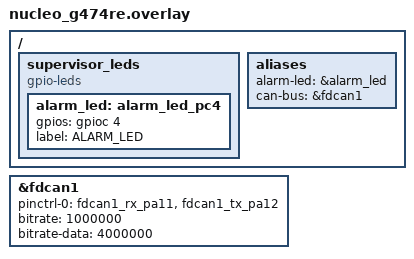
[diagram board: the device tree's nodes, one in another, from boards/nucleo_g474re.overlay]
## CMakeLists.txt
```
cmake_minimum_required(VERSION 3.20.0)

set(CMAKE_CXX_STANDARD 20)
set(CMAKE_CXX_STANDARD_REQUIRED ON)
set(CMAKE_CXX_EXTENSIONS OFF)

find_package(Zephyr REQUIRED HINTS $ENV{ZEPHYR_BASE})
project(supervisor_node LANGUAGES CXX)

target_sources(app PRIVATE
  ${CMAKE_CURRENT_SOURCE_DIR}/src/main.cpp
  ${CMAKE_CURRENT_SOURCE_DIR}/src/gpio_overlay.cpp
  ${CMAKE_CURRENT_SOURCE_DIR}/src/heartbeat_monitor.cpp
  ${CMAKE_CURRENT_SOURCE_DIR}/src/alarm_logic.cpp
  ${CMAKE_CURRENT_SOURCE_DIR}/src/supervisor_manager.cpp
  ${CMAKE_CURRENT_SOURCE_DIR}/../common/supervisor/src/can_bus_driver.cpp
  ${CMAKE_CURRENT_SOURCE_DIR}/../common/supervisor/src/message_codec.cpp
)

# Strict warnings apply only to our own application code, not to
# Zephyr's kernel/drivers/HAL/CMSIS sources (which are not -Werror clean
# on this toolchain and are not ours to fix).
target_compile_options(app PRIVATE
  -Wall
  -Wextra
  -Werror
  -Wvolatile
)

target_include_directories(app PRIVATE
  ${CMAKE_CURRENT_SOURCE_DIR}/include
  ${CMAKE_CURRENT_SOURCE_DIR}/../common/supervisor/include
)
```

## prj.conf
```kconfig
# ---- C++ support ------------------------------------------------------
CONFIG_CPP=y
CONFIG_STD_CPP20=y
CONFIG_NEWLIB_LIBC=y
CONFIG_GLIBCXX_LIBCPP=y

# ---- No heap allocation (Rule 1) --------------------------------------
CONFIG_HEAP_MEM_POOL_SIZE=0

# ---- Threading / stack watermarks (Rule 6) -----------------------------
CONFIG_THREAD_ANALYZER=y
CONFIG_THREAD_ANALYZER_AUTO=y
CONFIG_THREAD_NAME=y
CONFIG_MAIN_STACK_SIZE=2048

# ---- CAN-FD -------------------------------------------------------------
CONFIG_CAN=y
CONFIG_CAN_FD_MODE=y

# ---- GPIO (alarm LED) --------------------------------------------------
CONFIG_GPIO=y

# ---- Logging ----------------------------------------------------------
CONFIG_LOG=y
CONFIG_LOG_MODE_IMMEDIATE=y

# ---- Assertions ---------------------------------------------------------
CONFIG_ASSERT=y
```

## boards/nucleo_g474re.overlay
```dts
/*
 * Supervisor Node device tree overlay.
 * Binds: FDCAN1 (CAN bus), PC4 alarm LED.
 *
 * Application code SHALL NEVER reference these nodes directly; only
 * gpio_overlay.cpp is permitted to consume DT_ALIAS()/DT_NODELABEL()
 * macros generated from this file.
 */

&fdcan1 {
	status = "okay";
	pinctrl-0 = <&fdcan1_rx_pa11 &fdcan1_tx_pa12>;
	pinctrl-names = "default";
	bitrate = <1000000>;
	bitrate-data = <4000000>;
};

/ {
	supervisor_leds {
		compatible = "gpio-leds";
		alarm_led: alarm_led_pc4 {
			gpios = <&gpioc 4 GPIO_ACTIVE_HIGH>;
			label = "ALARM_LED";
		};
	};

	aliases {
		alarm-led = &alarm_led;
		can-bus = &fdcan1;
	};
};
```

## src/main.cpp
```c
/// @file main.cpp
/// @brief Supervisor Node entry point. Wires gpio_overlay -> CAN RX ->
///        supervisor_manager (Mediator) -> {alarm LED, RUN/STOP CAN TX}.
#include <zephyr/kernel.h>
#include <zephyr/logging/log.h>

#include "can_bus_driver.hpp"
#include "gpio_overlay.hpp"
#include "message_codec.hpp"
#include "supervisor_manager.hpp"

LOG_MODULE_REGISTER(supervisor_node_main, LOG_LEVEL_INF);

namespace {

using hce::supervisor_node::GpioOverlay;
using hce::supervisor_node::SupervisorManager;

constexpr uint32_t kMonitoringPeriodMs = 200U;
constexpr size_t kMonitorThreadStackSize = 2048U;
constexpr int kMonitorThreadPriority = 5;

GpioOverlay g_overlay;
hce::supervisor::CanBusDriver* g_can_bus = nullptr;
SupervisorManager* g_supervisor_manager = nullptr;

alignas(hce::supervisor::CanBusDriver) uint8_t g_can_bus_storage[sizeof(hce::supervisor::CanBusDriver)];
alignas(SupervisorManager) uint8_t g_supervisor_manager_storage[sizeof(SupervisorManager)];

/// @brief Copies an incoming CAN-FD frame's data bytes into a fixed-size
///        payload without any heap allocation.
hce::supervisor::MessageCodec::Payload ExtractPayload(const can_frame* frame) {
    hce::supervisor::MessageCodec::Payload payload{};
    for (uint8_t i = 0U; i < hce::supervisor::MessageCodec::kPayloadBytes && i < frame->dlc; ++i) {
        payload[i] = frame->data[i];
    }
    return payload;
}

extern "C" void OnPressureRx(const device* /*dev*/, can_frame* frame, void* /*user_data*/) {
    g_supervisor_manager->OnPressureReceived(ExtractPayload(frame));
}

extern "C" void OnFlowRx(const device* /*dev*/, can_frame* frame, void* /*user_data*/) {
    g_supervisor_manager->OnFlowReceived(ExtractPayload(frame));
}

extern "C" void OnSensorHeartbeatRx(const device* /*dev*/, can_frame* /*frame*/, void* /*user_data*/) {
    g_supervisor_manager->OnSensorHeartbeatReceived();
}

extern "C" void OnMotorHeartbeatRx(const device* /*dev*/, can_frame* /*frame*/, void* /*user_data*/) {
    g_supervisor_manager->OnMotorHeartbeatReceived();
}

void MonitorThreadEntry(void* /*p1*/, void* /*p2*/, void* /*p3*/) {
    while (true) {
        g_supervisor_manager->Tick();
        k_msleep(kMonitoringPeriodMs);
    }
}

K_THREAD_STACK_DEFINE(g_monitor_thread_stack, kMonitorThreadStackSize);
k_thread g_monitor_thread{};

}  // namespace

int main() {
    LOG_INF("Supervisor Node booting");

    if (!g_overlay.Init()) {
        LOG_ERR("gpio_overlay init failed - halting");
        return -1;
    }

    g_can_bus = new (g_can_bus_storage) hce::supervisor::CanBusDriver(g_overlay.CanDevice());
    g_supervisor_manager = new (g_supervisor_manager_storage) SupervisorManager(g_overlay, *g_can_bus);

    if (!g_can_bus->Init()) {
        LOG_ERR("CAN bus init failed - halting");
        return -1;
    }

    g_can_bus->AddRxFilter(hce::supervisor::CanId::kPressure, OnPressureRx, nullptr);
    g_can_bus->AddRxFilter(hce::supervisor::CanId::kFlow, OnFlowRx, nullptr);
    g_can_bus->AddRxFilter(hce::supervisor::CanId::kSensorHeartbeat, OnSensorHeartbeatRx, nullptr);
    g_can_bus->AddRxFilter(hce::supervisor::CanId::kMotorHeartbeat, OnMotorHeartbeatRx, nullptr);

    k_thread_create(&g_monitor_thread, g_monitor_thread_stack, kMonitorThreadStackSize,
                     MonitorThreadEntry, nullptr, nullptr, nullptr, kMonitorThreadPriority, 0,
                     K_NO_WAIT);
    k_thread_name_set(&g_monitor_thread, "supervisor_monitor");

    LOG_INF("Supervisor Node running");
    return 0;
}
```

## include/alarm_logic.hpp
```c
/// @file alarm_logic.hpp
/// @brief Combined pressure/flow/heartbeat fault evaluation.
///
/// Fault condition (per system safety spec):
///   (Pressure > kPressureThresholdPa AND Flow < kFlowThresholdLpm)
///   OR ThreeConsecutiveSensorHeartbeatsMissed
///   OR ThreeConsecutiveMotorHeartbeatsMissed
///
/// Note: pressure-high and flow-low are evaluated as a COMBINED condition
/// (both must be true together), not as two independent single-sensor
/// faults - this reflects a deliberate safety-logic update from
/// independent-fault evaluation to a combined-fault evaluation.
#pragma once

#include <cstdint>

namespace hce::supervisor_node {

/// @brief Inputs the alarm evaluation needs on any given tick.
struct AlarmInputs {
    float pressure_pa;
    bool pressure_valid;
    float flow_lpm;
    bool flow_valid;
    bool sensor_heartbeat_faulted;
    bool motor_heartbeat_faulted;
};

/// @brief Stateless fault-evaluation strategy (Strategy pattern: the
///        evaluation rule is isolated behind Evaluate() so it can be
///        swapped/tested independently of CAN transport or GPIO).
class AlarmLogic {
public:
    static constexpr float kPressureThresholdPa = 1025.0F;
    static constexpr float kFlowThresholdLpm = 60.0F;

    /// @brief Evaluate the combined fault condition.
    /// @return true if a fault (STOP condition) is present.
    bool Evaluate(const AlarmInputs& inputs) const;
};

}  // namespace hce::supervisor_node
```

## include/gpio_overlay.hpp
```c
/// @file gpio_overlay.hpp
/// @brief Sole layer permitted to reference Device Tree bindings for the
///        Supervisor Node.
#pragma once

#include <cstdint>

#include <zephyr/device.h>
#include <zephyr/drivers/gpio.h>

namespace hce::supervisor_node {

/// @brief Thin, mockable wrapper around all Supervisor Node DT-bound devices.
class GpioOverlay {
public:
    GpioOverlay() = default;

    bool Init();

    /// @brief CAN-FD controller device (FDCAN1).
    const device* CanDevice() const { return can_dev_; }

    /// @brief Drive the alarm LED (PC4).
    bool SetAlarmLed(bool on);

private:
    const device* can_dev_ = nullptr;
    gpio_dt_spec alarm_led_spec_{};
    bool initialized_ = false;
};

}  // namespace hce::supervisor_node
```

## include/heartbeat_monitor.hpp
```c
/// @file heartbeat_monitor.hpp
/// @brief Tracks liveness of the Sensor Node and Motor Node heartbeats.
///        A node is declared faulted after three consecutive missed
///        heartbeats (600 ms at the 200 ms heartbeat period).
#pragma once

#include <cstdint>

namespace hce::supervisor_node {

/// @brief Per-remote-node liveness tracker.
class NodeLivenessTracker {
public:
    static constexpr uint8_t kMaxConsecutiveMisses = 3U;

    /// @brief Call when a heartbeat frame is received from this node.
    void OnHeartbeatReceived();

    /// @brief Call once per supervisor monitoring tick (200 ms) to age
    ///        out the current window and evaluate for missed heartbeats.
    void OnMonitoringTick();

    /// @brief true if the node has missed kMaxConsecutiveMisses in a row.
    bool IsFaulted() const { return consecutive_misses_ >= kMaxConsecutiveMisses; }

private:
    uint8_t consecutive_misses_ = 0U;
    bool received_since_last_tick_ = false;
};

/// @brief Aggregates liveness for both remote nodes the Supervisor watches.
class HeartbeatMonitor {
public:
    void OnSensorHeartbeatReceived() { sensor_tracker_.OnHeartbeatReceived(); }
    void OnMotorHeartbeatReceived() { motor_tracker_.OnHeartbeatReceived(); }

    /// @brief Call once per 200 ms supervisor monitoring tick.
    void OnMonitoringTick();

    bool IsSensorNodeFaulted() const { return sensor_tracker_.IsFaulted(); }
    bool IsMotorNodeFaulted() const { return motor_tracker_.IsFaulted(); }

private:
    NodeLivenessTracker sensor_tracker_;
    NodeLivenessTracker motor_tracker_;
};

}  // namespace hce::supervisor_node
```

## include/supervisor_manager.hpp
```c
/// @file supervisor_manager.hpp
/// @brief Mediator between CAN RX (pressure/flow/heartbeats), alarm_logic,
///        heartbeat_monitor and CAN TX (RUN/STOP). Implements the Mediator
///        design pattern (Rule 4): CAN input handling, fault evaluation and
///        command dispatch never reference each other directly, only
///        through SupervisorManager.
#pragma once

#include <cstdint>

#include "alarm_logic.hpp"
#include "can_bus_driver.hpp"
#include "gpio_overlay.hpp"
#include "heartbeat_monitor.hpp"
#include "message_codec.hpp"

namespace hce::supervisor_node {

/// @brief Supervisor RUN/STOP output state.
enum class SupervisorState : uint8_t {
    kRun = 0U,
    kStop = 1U,
};

/// @brief Top-level Supervisor Node coordinator.
class SupervisorManager {
public:
    SupervisorManager(GpioOverlay& overlay, hce::supervisor::ICanBusDriver& can_bus);

    // ---- CAN RX handlers (called from ISR-safe deferred context) --------
    void OnPressureReceived(const hce::supervisor::MessageCodec::Payload& payload);
    void OnFlowReceived(const hce::supervisor::MessageCodec::Payload& payload);
    void OnSensorHeartbeatReceived();
    void OnMotorHeartbeatReceived();

    /// @brief Evaluate fault logic and drive alarm LED + RUN/STOP CAN
    ///        output. Intended to be called every 200 ms (Supervisor
    ///        Monitoring period) from a dedicated thread.
    void Tick();

    SupervisorState State() const { return state_; }

private:
    void TransmitStopCommand();
    void TransmitRunCommand();

    GpioOverlay& overlay_;
    hce::supervisor::ICanBusDriver& can_bus_;
    HeartbeatMonitor heartbeat_monitor_;
    AlarmLogic alarm_logic_;

    float latest_pressure_pa_ = 0.0F;
    bool pressure_valid_ = false;
    float latest_flow_lpm_ = 0.0F;
    bool flow_valid_ = false;

    SupervisorState state_ = SupervisorState::kStop;

    static constexpr uint32_t kDefaultRunStepRateHz = 400U;
};

}  // namespace hce::supervisor_node
```

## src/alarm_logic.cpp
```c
#include "alarm_logic.hpp"

namespace hce::supervisor_node {

bool AlarmLogic::Evaluate(const AlarmInputs& inputs) const {
    const bool pressure_high = inputs.pressure_valid && (inputs.pressure_pa > kPressureThresholdPa);
    const bool flow_low = inputs.flow_valid && (inputs.flow_lpm < kFlowThresholdLpm);

    // Combined condition: BOTH pressure-high AND flow-low must hold
    // together to raise a sensor-side fault (see file header note).
    const bool combined_sensor_fault = pressure_high && flow_low;

    return combined_sensor_fault || inputs.sensor_heartbeat_faulted ||
           inputs.motor_heartbeat_faulted;
}

}  // namespace hce::supervisor_node
```

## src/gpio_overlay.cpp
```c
#include "gpio_overlay.hpp"

#include <zephyr/devicetree.h>
#include <zephyr/logging/log.h>

LOG_MODULE_REGISTER(supervisor_gpio_overlay, LOG_LEVEL_INF);

namespace hce::supervisor_node {

bool GpioOverlay::Init() {
    can_dev_ = DEVICE_DT_GET(DT_ALIAS(can_bus));
    alarm_led_spec_ = GPIO_DT_SPEC_GET(DT_ALIAS(alarm_led), gpios);

    if (!device_is_ready(can_dev_) || !device_is_ready(alarm_led_spec_.port)) {
        LOG_ERR("One or more Supervisor Node devices are not ready");
        return false;
    }

    const int err = gpio_pin_configure_dt(&alarm_led_spec_, GPIO_OUTPUT_INACTIVE);
    if (err != 0) {
        LOG_ERR("Failed to configure alarm LED: %d", err);
        return false;
    }

    initialized_ = true;
    return true;
}

bool GpioOverlay::SetAlarmLed(bool on) {
    if (!initialized_) {
        return false;
    }
    return gpio_pin_set_dt(&alarm_led_spec_, on ? 1 : 0) == 0;
}

}  // namespace hce::supervisor_node
```

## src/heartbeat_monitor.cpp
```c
#include "heartbeat_monitor.hpp"

namespace hce::supervisor_node {

void NodeLivenessTracker::OnHeartbeatReceived() {
    received_since_last_tick_ = true;
}

void NodeLivenessTracker::OnMonitoringTick() {
    if (received_since_last_tick_) {
        consecutive_misses_ = 0U;
    } else if (consecutive_misses_ < kMaxConsecutiveMisses) {
        ++consecutive_misses_;
    }
    received_since_last_tick_ = false;
}

void HeartbeatMonitor::OnMonitoringTick() {
    sensor_tracker_.OnMonitoringTick();
    motor_tracker_.OnMonitoringTick();
}

}  // namespace hce::supervisor_node
```

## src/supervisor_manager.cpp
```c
#include "supervisor_manager.hpp"

namespace hce::supervisor_node {

SupervisorManager::SupervisorManager(GpioOverlay& overlay, hce::supervisor::ICanBusDriver& can_bus)
    : overlay_(overlay), can_bus_(can_bus) {}

void SupervisorManager::OnPressureReceived(const hce::supervisor::MessageCodec::Payload& payload) {
    const hce::supervisor::PressureMessage msg = hce::supervisor::MessageCodec::DecodePressure(payload);
    latest_pressure_pa_ = msg.pressure_pa;
    pressure_valid_ = true;
}

void SupervisorManager::OnFlowReceived(const hce::supervisor::MessageCodec::Payload& payload) {
    const hce::supervisor::FlowMessage msg = hce::supervisor::MessageCodec::DecodeFlow(payload);
    latest_flow_lpm_ = msg.flow_lpm;
    flow_valid_ = true;
}

void SupervisorManager::OnSensorHeartbeatReceived() {
    heartbeat_monitor_.OnSensorHeartbeatReceived();
}

void SupervisorManager::OnMotorHeartbeatReceived() {
    heartbeat_monitor_.OnMotorHeartbeatReceived();
}

void SupervisorManager::TransmitStopCommand() {
    hce::supervisor::StopCommandMessage msg{};
    msg.reserved = 0U;
    const hce::supervisor::MessageCodec::Payload payload = hce::supervisor::MessageCodec::EncodeStopCommand(msg);
    can_bus_.Send(hce::supervisor::CanId::kStopCommand, payload.data(),
                   hce::supervisor::MessageCodec::kPayloadBytes);
}

void SupervisorManager::TransmitRunCommand() {
    hce::supervisor::RunCommandMessage msg{};
    msg.step_rate_hz = kDefaultRunStepRateHz;
    msg.direction = 0U;
    const hce::supervisor::MessageCodec::Payload payload = hce::supervisor::MessageCodec::EncodeRunCommand(msg);
    can_bus_.Send(hce::supervisor::CanId::kRunCommand, payload.data(),
                   hce::supervisor::MessageCodec::kPayloadBytes);
}

void SupervisorManager::Tick() {
    heartbeat_monitor_.OnMonitoringTick();

    AlarmInputs inputs{};
    inputs.pressure_pa = latest_pressure_pa_;
    inputs.pressure_valid = pressure_valid_;
    inputs.flow_lpm = latest_flow_lpm_;
    inputs.flow_valid = flow_valid_;
    inputs.sensor_heartbeat_faulted = heartbeat_monitor_.IsSensorNodeFaulted();
    inputs.motor_heartbeat_faulted = heartbeat_monitor_.IsMotorNodeFaulted();

    const bool faulted = alarm_logic_.Evaluate(inputs);
    overlay_.SetAlarmLed(faulted);

    const SupervisorState new_state = faulted ? SupervisorState::kStop : SupervisorState::kRun;
    if (new_state != state_ || faulted) {
        // STOP is re-broadcast every tick while faulted (fail-safe,
        // handles a Motor Node that boots or reconnects mid-fault).
        if (new_state == SupervisorState::kStop) {
            TransmitStopCommand();
        } else {
            TransmitRunCommand();
        }
    }
    state_ = new_state;
}

}  // namespace hce::supervisor_node
```
